# PIC18F26Q83 register map
Vendor: Microchip
Registers are 8-bit, read-write, reset 0x0 unless marked. A register's access mark holds for its fields unless they carry their own. Addresses are absolute, and some are shared; only a register's first bit layout is shown; [hi:lo] are bit positions; {n}, {i} and the like mark numbered series.

## CONFIG (part 1 of 3) — Configuration words, addresses in ProgramSpace
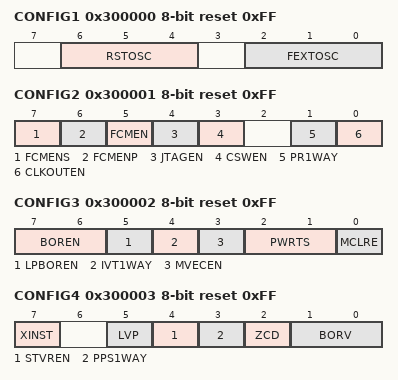
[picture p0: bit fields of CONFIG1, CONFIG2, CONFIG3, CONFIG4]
0x300000 CONFIG1 reset 0xFF — Configuration Byte 1
  [6:4] RSTOSC — Reset Oscillator Selection
    0=HFINTOSC_64MHZ (HFINTOSC with HFFRQ = 64 MHz and CDIV = 1:1); 2=EXTOSC_4PLL (EXTOSC with 4x PLL, with EXTOSC operating per FEXTOSC bits); 4=SOSC (Secondary Oscillator); 5=LFINTOSC (Low-Frequency Oscillator); 6=HFINTOSC_1MHZ (HFINTOSC with HFFRQ = 4 MHz and CDIV = 4:1); 7=EXTOSC (EXTOSC operating per FEXTOSC bits (device manufacturing default))
  [2:0] FEXTOSC — External Oscillator Selection
    0=LP (LP (crystal oscillator) optimized for 32.768 kHz); 1=XT (XT (crystal oscillator) above 100 kHz, below 8 MHz); 2=HS (HS (crystal oscillator) above 8 MHz); 4=OFF (Oscillator not enabled); 5=ECL (EC (external clock) below 100 kHz); 6=ECM (EC (external clock) for 500 kHz to 8 MHz); 7=ECH (EC (external clock) above 8 MHz)
0x300001 CONFIG2 reset 0xFF — Configuration byte 2
  [7] FCMENS — Fail-Safe Clock Monitor -Secondary XTAL Enable bit
    0=OFF (FSCM timer will not set FSCMS bit or OSFIF interrupt on Secondary XTAL failure); 1=ON (FSCM timer will set FSCMS bit and OSFIF interrupt on Secondary XTAL failure)
  [6] FCMENP — Fail-Safe Clock Monitor -Primary XTAL Enable bit
    0=OFF (FSCM timer will not set FSCMP bit or OSFIF interrupt on Primary XTAL failure); 1=ON (FSCM timer will set FSCMP bit and OSFIF interrupt on Primary XTAL failure)
  [5] FCMEN — Fail-Safe Clock Monitor Enable bit
    0=OFF (Fail-Safe Clock Monitor disabled); 1=ON (Fail-Safe Clock Monitor enabled)
  [4] JTAGEN — JTAG Enable bit
    1=ON (Enable JTAG Boundary Scan mode and pins); 0=OFF (Disable JTAG Boundary Scan mode, JTAG pins revert to user functions)
  [3] CSWEN — Clock Switch Enable bit
    0=OFF (The NOSC and NDIV bits cannot be changed by user software); 1=ON (Writing to NOSC and NDIV is allowed)
  [1] PR1WAY — PRLOCKED One-Way Set Enable bit
    1=ON (PRLOCKED bit can be cleared and set only once); 0=OFF (PRLOCKED bit can be set and cleared repeatedly)
  [0] CLKOUTEN — Clock out Enable bit
    1=OFF (CLKOUT function is disabled); 0=ON (CLKOUT function is enabled)
0x300002 CONFIG3 reset 0xFF — Configuration byte 3
  [7:6] BOREN — Brown-out Reset Enable bits
    3=SBORDIS (Brown-out Reset enabled , SBOREN bit is ignored); 2=NOSLP (Brown-out Reset enabled while running, disabled in Sleep; SBOREN is ignored); 1=ON (Brown-out Reset enabled according to SBOREN); 0=OFF (Brown-out Reset disabled)
  [5] LPBOREN — Low Power BOR Enable bit
    1=OFF (Low-Power BOR disabled); 0=ON (Low-Power BOR enabled)
  [4] IVT1WAY — IVTLOCK bit One-way set enable bit
    1=ON (IVTLOCKED bit can be cleared and set only once); 0=OFF (IVTLOCKED bit can be cleared and set repeatedly)
  [3] MVECEN — Multi-vector enable bit
    1=ON (Multi-vector enabled, Vector table used for interrupts); 0=OFF (Interrupt contoller does not use vector table to prioritze interrupts)
  [2:1] PWRTS — Power-up timer selection bits
    3=PWRT_OFF (PWRT is disabled); 2=PWRT_64 (PWRT set at 64ms); 1=PWRT_16 (PWRT set at 16ms); 0=PWRT_1 (PWRT set at 1ms)
  [0] MCLRE — MCLR Enable bit
    1=EXTMCLR (If LVP = 0, MCLR pin is MCLR; If LVP = 1, RE3 pin function is MCLR); 0=INTMCLR (If LVP = 0, MCLR pin function is port defined function; If LVP =1, RE3 pin fuction is MCLR)
0x300003 CONFIG4 reset 0xFF — Configuration byte 4
  [7] XINST — Extended Instruction Set Enable bit
    1=OFF (Extended Instruction Set and Indexed Addressing Mode disabled); 0=ON (Extended Instruction Set and Indexed Addressing Mode enabled)
  [5] LVP — Low Voltage Programming Enable bit
    1=ON (Low voltage programming enabled. MCLR/VPP pin function is MCLR. MCLRE configuration bit is ignored); 0=OFF (HV on MCLR/VPP must be used for programming)
  [4] STVREN — Stack Full/Underflow Reset Enable bit
    1=ON (Stack full/underflow will cause Reset); 0=OFF (Stack full/underflow will not cause Reset)
  [3] PPS1WAY — PPSLOCK bit One-Way Set Enable bit
    1=ON (PPSLOCKED bit can be cleared and set only once; PPS registers remain locked after one clear/set cycle); 0=OFF (PPSLOCKED bit can be set and cleared repeatedly (subject to the unlock sequence))
  [2] ZCD — ZCD Disable bit
    1=OFF (ZCD module is disabled. ZCD can be enabled by setting the ZCDSEN bit of ZCDCON); 0=ON (ZCD module is always enabled; ZCDMD and ZCDSEN bits are ignored)
  [1:0] BORV — Brown-out Reset Voltage Selection bits
    3=VBOR_1P9 (Brown-out Reset Voltage (VBOR) set to 1.9V); 2=VBOR_2P45 (Brown-out Reset Voltage (VBOR) set to 2.45V); 1=VBOR_2P7 (Brown-out Reset Voltage (VBOR) set to 2.7V); 0=VBOR_2P85 (Brown-out Reset Voltage (VBOR) set to 2.8V)
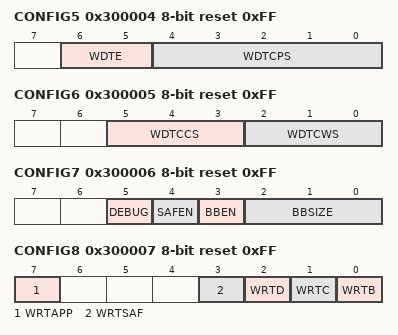
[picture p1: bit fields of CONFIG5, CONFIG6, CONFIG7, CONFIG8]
0x300004 CONFIG5 reset 0xFF — Configuration byte 5
  [6:5] WDTE — WDT operating mode
    0=OFF (WDT Disabled; SWDTEN is ignored); 1=SWDTEN (WDT enabled/disabled by SWDTEN bit); 2=NSLEEP (WDT enabled while sleep=0, suspended when sleep=1; SWDTEN ignored); 3=ON (WDT enabled regardless of sleep; SWDTEN is ignored)
  [4:0] WDTCPS — WDT Period selection bits
    0=Divider ratio 1:32; 1=Divider ratio 1:64; 2=Divider ratio 1:128; 3=Divider ratio 1:256; 4=Divider ratio 1:512; 5=Divider ratio 1:1024; 6=Divider ratio 1:2048; 7=Divider ratio 1:4096; 8=Divider ratio 1:8192; 9=Divider ratio 1:16384; 10=Divider ratio 1:32768; 11=Divider ratio 1:65536; 12=Divider ratio 1:131072; 13=Divider ratio 1:262144; 14=Divider ratio 1:524299; 15=Divider ratio 1:1048576; 16=Divider ratio 1:2097152; 17=Divider ratio 1:4194304; 18=Divider ratio 1:8388608; {v}=Divider ratio 1:32 (v=19..30); 31=Divider ratio 1:65536; software control of WDTPS
0x300005 CONFIG6 reset 0xFF — Configuration byte 6
  [5:3] WDTCCS — WDT input clock selector
    0=LFINTOSC (WDT reference clock is the 31.0 kHz LFINTOSC); 1=MFINTOSC (WDT reference clock is the 32kHz MFINTOSC output); 2=SOSC (WDT reference clock is SOSC); 7=SC (Software Control)
  [2:0] WDTCWS — WDT Window Select bits
    0=window delay = 87.5; no software control; keyed access required; 1=window delay = 75 percent of time; no software control; keyed access required; 2=window delay = 62.5 percent of time; no software control; keyed access required; 3=window delay = 50 percent of time; no software control; keyed access required; 4=window delay = 37.5 percent of time; no software control; keyed access required; 5=window delay = 25 percent of time; no software control; keyed access required; 6=window always open (100%); no software control; keyed access required; 7=window always open (100%); software control; keyed access not required
0x300006 CONFIG7 reset 0xFF — Configuration byte 7
  [5] DEBUG — Background Debugger
    1=OFF (Background Debugger disabled); 0=ON (background debugger enabled)
  [4] SAFEN — Storage Area Flash enable bit
    1=OFF (SAF disabled); 0=ON (SAF enabled)
  [3] BBEN — Boot Block enable bit
    1=OFF (Boot block disabled); 0=ON (Boot block enabled)
  [2:0] BBSIZE — Boot Block Size selection bits
    7=Boot Block size is 512 words; 6=Boot Block size is 1024 words; 5=Boot Block size is 2048 words; 4=Boot Block size is 4096 words; 3=Boot Block size is 8192 words; 2=Boot Block size is 16384 words; 1=Boot Block size is 32768 words
0x300007 CONFIG8 reset 0xFF — Configuration byte 8
  [7] WRTAPP — Application Block write protection bit
    1=OFF (Application Block not write protected); 0=ON (Application Block write protected)
  [3] WRTSAF — SAF Write protection bit
    1=OFF (SAF not Write Protected); 0=ON (SAF Write Protected)
  [2] WRTD — Data EEPROM Write Protection bit
    1=OFF (Data EEPROM not Write protected); 0=ON (Data EEPROM Write protected)
  [1] WRTC — Configuration Register Write Protection bit
    1=OFF (Configuration registers not Write protected); 0=ON (Configuration registers Write protected)
  [0] WRTB — Boot Block Write Protection bit
    1=OFF (Boot Block not Write protected); 0=ON (Boot Block Write protected)
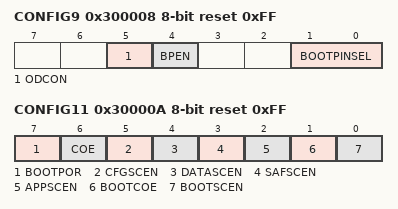
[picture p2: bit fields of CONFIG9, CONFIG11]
0x300008 CONFIG9 reset 0xFF
  [5] ODCON — CRC on boot output pin open drain bit
    1=OFF (Pin drives both high-going and low-going signals); 0=ON (Pin drives only low-going signals)
  [4] BPEN — CRC on boot output pin enable bit
    1=OFF (CRC on boot output pin disabled); 0=ON (CRC on boot output pin enabled, selected by BOOTPINSEL<1:0>)
  [1:0] BOOTPINSEL — CRC on boot output pin selection
    0=RA4 (CRC on boot output pin is RA4); 1=RA2 (CRC on boot output pin is RA2); 2=RC4 (CRC on boot output pin is RC4); 3=RC5 (CRC on boot output pin is RC5)
0x300009 CONFIG10 reset 0xFF — Configuration byte 10
  [0] CP — PFM and Data EEPROM Code Protection bit
    1=OFF (PFM and Data EEPROM code protection disabled); 0=ON (PFM and Data EEPROM code protection enabled)
0x30000A CONFIG11 reset 0xFF
  [7] BOOTPOR — Boot on CRC Enable bit
    1=OFF (CRC on boot will not run); 0=ON (CRC on boot will run)
  [6] COE — CRC on boot Continue on Error for non-boot areas bit
    1=HALT (CRC on boot will stop device if error is detected in non-boot areas); 0=CONTINUE (CRC on boot will allow device to continue code execution regardless of error detection in non-boot areas)
  [5] CFGSCEN — CRC on boot Config fuses scan enable
    1=OFF (CRC on boot will not include the configuration fuses in its calculation); 0=ON (CRC on boot will include the configuration fuses in its calculation)
  [4] DATASCEN — CRC on boot Data EEPROM scan enable
    1=OFF (CRC on boot will not include data EEPROM in its calculation); 0=ON (CRC on boot will include data EEPROM in its calculation)
  [3] SAFSCEN — CRC on boot SAF area scan enable
    1=OFF (CRC on boot will not include the SAF area of program memory in its calculation); 0=ON (CRC on boot will include the SAF area of program memory in its calculation)
  [2] APPSCEN — CRC on boot application code scan enable
    1=OFF (CRC on boot will not include the application area of program memory in its calculation); 0=ON (CRC on boot will include the application area of program memory in its calculation)
  [1] BOOTCOE — CRC on boot Continue on Error for boot areas bit
    1=HALT (CRC on boot will stop device if error is detected in boot areas); 0=CONTINUE (CRC on boot will allow device to continue code execution regardless of error detection in boot areas)
  [0] BOOTSCEN — CRC on boot scan enable for boot area
    1=OFF (CRC on boot will not include the boot area of program memory in its calculation); 0=ON (CRC on boot will include the boot area of program memory in its calculation)
0x30000B CONFIG12 reset 0xFF — Boot Sector Polynomial for CRC on boot bits 31-24
  [7:0] BCRCPOLT
    {v}=h{v:02} (Bits 31:24 of BCRCPOL are {0x0+v}) (v=0..9); 10=h0A (Bits 31:24 of BCRCPOL are 0x0A); 11=h0B (Bits 31:24 of BCRCPOL are 0x0B); 12=h0C (Bits 31:24 of BCRCPOL are 0x0C); 13=h0D (Bits 31:24 of BCRCPOL are 0x0D); 14=h0E (Bits 31:24 of BCRCPOL are 0x0E); 15=h0F (Bits 31:24 of BCRCPOL are 0x0F); {v}=h{v-6} (Bits 31:24 of BCRCPOL are {0x0+v}) (v=16..25); 26=h1A (Bits 31:24 of BCRCPOL are 0x1A); 27=h1B (Bits 31:24 of BCRCPOL are 0x1B); 28=h1C (Bits 31:24 of BCRCPOL are 0x1C); 29=h1D (Bits 31:24 of BCRCPOL are 0x1D); 30=h1E (Bits 31:24 of BCRCPOL are 0x1E); 31=h1F (Bits 31:24 of BCRCPOL are 0x1F); {v}=h{v-12} (Bits 31:24 of BCRCPOL are {0x0+v}) (v=32..41); 42=h2A (Bits 31:24 of BCRCPOL are 0x2A); 43=h2B (Bits 31:24 of BCRCPOL are 0x2B); 44=h2C (Bits 31:24 of BCRCPOL are 0x2C); 45=h2D (Bits 31:24 of BCRCPOL are 0x2D); 46=h2E (Bits 31:24 of BCRCPOL are 0x2E); 47=h2F (Bits 31:24 of BCRCPOL are 0x2F); {v}=h{v-18} (Bits 31:24 of BCRCPOL are {0x0+v}) (v=48..57); 58=h3A (Bits 31:24 of BCRCPOL are 0x3A); 59=h3B (Bits 31:24 of BCRCPOL are 0x3B); 60=h3C (Bits 31:24 of BCRCPOL are 0x3C); 61=h3D (Bits 31:24 of BCRCPOL are 0x3D); 62=h3E (Bits 31:24 of BCRCPOL are 0x3E); 63=h3F (Bits 31:24 of BCRCPOL are 0x3F); {v}=h{v-24} (Bits 31:24 of BCRCPOL are {0x0+v}) (v=64..73); 74=h4A (Bits 31:24 of BCRCPOL are 0x4A); 75=h4B (Bits 31:24 of BCRCPOL are 0x4B); 76=h4C (Bits 31:24 of BCRCPOL are 0x4C); 77=h4D (Bits 31:24 of BCRCPOL are 0x4D); 78=h4E (Bits 31:24 of BCRCPOL are 0x4E); 79=h4F (Bits 31:24 of BCRCPOL are 0x4F); {v}=h{v-30} (Bits 31:24 of BCRCPOL are {0x0+v}) (v=80..89); 90=h5A (Bits 31:24 of BCRCPOL are 0x5A); 91=h5B (Bits 31:24 of BCRCPOL are 0x5B); 92=h5C (Bits 31:24 of BCRCPOL are 0x5C); 93=h5D (Bits 31:24 of BCRCPOL are 0x5D); 94=h5E (Bits 31:24 of BCRCPOL are 0x5E); 95=h5F (Bits 31:24 of BCRCPOL are 0x5F); {v}=h{v-36} (Bits 31:24 of BCRCPOL are {0x0+v}) (v=96..105); 106=h6A (Bits 31:24 of BCRCPOL are 0x6A); 107=h6B (Bits 31:24 of BCRCPOL are 0x6B); 108=h6C (Bits 31:24 of BCRCPOL are 0x6C); 109=h6D (Bits 31:24 of BCRCPOL are 0x6D); 110=h6E (Bits 31:24 of BCRCPOL are 0x6E); 111=h6F (Bits 31:24 of BCRCPOL are 0x6F); {v}=h{v-42} (Bits 31:24 of BCRCPOL are {0x0+v}) (v=112..121); 122=h7A (Bits 31:24 of BCRCPOL are 0x7A); 123=h7B (Bits 31:24 of BCRCPOL are 0x7B); 124=h7C (Bits 31:24 of BCRCPOL are 0x7C); 125=h7D (Bits 31:24 of BCRCPOL are 0x7D); 126=h7E (Bits 31:24 of BCRCPOL are 0x7E); 127=h7F (Bits 31:24 of BCRCPOL are 0x7F); {v}=h{v-48} (Bits 31:24 of BCRCPOL are {0x0+v}) (v=128..137); 138=h8A (Bits 31:24 of BCRCPOL are 0x8A); 139=h8B (Bits 31:24 of BCRCPOL are 0x8B); 140=h8C (Bits 31:24 of BCRCPOL are 0x8C); 141=h8D (Bits 31:24 of BCRCPOL are 0x8D); 142=h8E (Bits 31:24 of BCRCPOL are 0x8E); 143=h8F (Bits 31:24 of BCRCPOL are 0x8F); {v}=h{v-54} (Bits 31:24 of BCRCPOL are {0x0+v}) (v=144..153); 154=h9A (Bits 31:24 of BCRCPOL are 0x9A); 155=h9B (Bits 31:24 of BCRCPOL are 0x9B); 156=h9C (Bits 31:24 of BCRCPOL are 0x9C); 157=h9D (Bits 31:24 of BCRCPOL are 0x9D); 158=h9E (Bits 31:24 of BCRCPOL are 0x9E); 159=h9F (Bits 31:24 of BCRCPOL are 0x9F); {v}=hA{v-160} (Bits 31:24 of BCRCPOL are {0x0+v}) (v=160..169); 170=hAA (Bits 31:24 of BCRCPOL are 0xAA); 171=hAB (Bits 31:24 of BCRCPOL are 0xAB); 172=hAC (Bits 31:24 of BCRCPOL are 0xAC); 173=hAD (Bits 31:24 of BCRCPOL are 0xAD); 174=hAE (Bits 31:24 of BCRCPOL are 0xAE); 175=hAF (Bits 31:24 of BCRCPOL are 0xAF); {v}=hB{v-176} (Bits 31:24 of BCRCPOL are {0x0+v}) (v=176..185); 186=hBA (Bits 31:24 of BCRCPOL are 0xBA); 187=hBB (Bits 31:24 of BCRCPOL are 0xBB); 188=hBC (Bits 31:24 of BCRCPOL are 0xBC); 189=hBD (Bits 31:24 of BCRCPOL are 0xBD); 190=hBE (Bits 31:24 of BCRCPOL are 0xBE); 191=hBF (Bits 31:24 of BCRCPOL are 0xBF); {v}=hC{v-192} (Bits 31:24 of BCRCPOL are {0x0+v}) (v=192..201); 202=hCA (Bits 31:24 of BCRCPOL are 0xCA); 203=hCB (Bits 31:24 of BCRCPOL are 0xCB); 204=hCC (Bits 31:24 of BCRCPOL are 0xCC); 205=hCD (Bits 31:24 of BCRCPOL are 0xCD); 206=hCE (Bits 31:24 of BCRCPOL are 0xCE); 207=hCF (Bits 31:24 of BCRCPOL are 0xCF); {v}=hD{v-208} (Bits 31:24 of BCRCPOL are {0x0+v}) (v=208..217); 218=hDA (Bits 31:24 of BCRCPOL are 0xDA); 219=hDB (Bits 31:24 of BCRCPOL are 0xDB); 220=hDC (Bits 31:24 of BCRCPOL are 0xDC); 221=hDD (Bits 31:24 of BCRCPOL are 0xDD); 222=hDE (Bits 31:24 of BCRCPOL are 0xDE); 223=hDF (Bits 31:24 of BCRCPOL are 0xDF); {v}=hE{v-224} (Bits 31:24 of BCRCPOL are {0x0+v}) (v=224..233); 234=hEA (Bits 31:24 of BCRCPOL are 0xEA); 235=hEB (Bits 31:24 of BCRCPOL are 0xEB); 236=hEC (Bits 31:24 of BCRCPOL are 0xEC); 237=hED (Bits 31:24 of BCRCPOL are 0xED); 238=hEE (Bits 31:24 of BCRCPOL are 0xEE); 239=hEF (Bits 31:24 of BCRCPOL are 0xEF); {v}=hF{v-240} (Bits 31:24 of BCRCPOL are {0x0+v}) (v=240..249); 250=hFA (Bits 31:24 of BCRCPOL are 0xFA); 251=hFB (Bits 31:24 of BCRCPOL are 0xFB); 252=hFC (Bits 31:24 of BCRCPOL are 0xFC); 253=hFD (Bits 31:24 of BCRCPOL are 0xFD); 254=hFE (Bits 31:24 of BCRCPOL are 0xFE); 255=hFF (Bits 31:24 of BCRCPOL are 0xFF)
0x30000C CONFIG13 reset 0xFF — Boot Sector Polynomial for CRC on boot bits 23-16
  [7:0] BCRCPOLU
    {v}=h{v:02} (Bits 23:16 of BCRCPOL are {0x0+v}) (v=0..9); 10=h0A (Bits 23:16 of BCRCPOL are 0x0A); 11=h0B (Bits 23:16 of BCRCPOL are 0x0B); 12=h0C (Bits 23:16 of BCRCPOL are 0x0C); 13=h0D (Bits 23:16 of BCRCPOL are 0x0D); 14=h0E (Bits 23:16 of BCRCPOL are 0x0E); 15=h0F (Bits 23:16 of BCRCPOL are 0x0F); {v}=h{v-6} (Bits 23:16 of BCRCPOL are {0x0+v}) (v=16..25); 26=h1A (Bits 23:16 of BCRCPOL are 0x1A); 27=h1B (Bits 23:16 of BCRCPOL are 0x1B); 28=h1C (Bits 23:16 of BCRCPOL are 0x1C); 29=h1D (Bits 23:16 of BCRCPOL are 0x1D); 30=h1E (Bits 23:16 of BCRCPOL are 0x1E); 31=h1F (Bits 23:16 of BCRCPOL are 0x1F); {v}=h{v-12} (Bits 23:16 of BCRCPOL are {0x0+v}) (v=32..41); 42=h2A (Bits 23:16 of BCRCPOL are 0x2A); 43=h2B (Bits 23:16 of BCRCPOL are 0x2B); 44=h2C (Bits 23:16 of BCRCPOL are 0x2C); 45=h2D (Bits 23:16 of BCRCPOL are 0x2D); 46=h2E (Bits 23:16 of BCRCPOL are 0x2E); 47=h2F (Bits 23:16 of BCRCPOL are 0x2F); {v}=h{v-18} (Bits 23:16 of BCRCPOL are {0x0+v}) (v=48..57); 58=h3A (Bits 23:16 of BCRCPOL are 0x3A); 59=h3B (Bits 23:16 of BCRCPOL are 0x3B); 60=h3C (Bits 23:16 of BCRCPOL are 0x3C); 61=h3D (Bits 23:16 of BCRCPOL are 0x3D); 62=h3E (Bits 23:16 of BCRCPOL are 0x3E); 63=h3F (Bits 23:16 of BCRCPOL are 0x3F); {v}=h{v-24} (Bits 23:16 of BCRCPOL are {0x0+v}) (v=64..73); 74=h4A (Bits 23:16 of BCRCPOL are 0x4A); 75=h4B (Bits 23:16 of BCRCPOL are 0x4B); 76=h4C (Bits 23:16 of BCRCPOL are 0x4C); 77=h4D (Bits 23:16 of BCRCPOL are 0x4D); 78=h4E (Bits 23:16 of BCRCPOL are 0x4E); 79=h4F (Bits 23:16 of BCRCPOL are 0x4F); {v}=h{v-30} (Bits 23:16 of BCRCPOL are {0x0+v}) (v=80..89); 90=h5A (Bits 23:16 of BCRCPOL are 0x5A); 91=h5B (Bits 23:16 of BCRCPOL are 0x5B); 92=h5C (Bits 23:16 of BCRCPOL are 0x5C); 93=h5D (Bits 23:16 of BCRCPOL are 0x5D); 94=h5E (Bits 23:16 of BCRCPOL are 0x5E); 95=h5F (Bits 23:16 of BCRCPOL are 0x5F); {v}=h{v-36} (Bits 23:16 of BCRCPOL are {0x0+v}) (v=96..105); 106=h6A (Bits 23:16 of BCRCPOL are 0x6A); 107=h6B (Bits 23:16 of BCRCPOL are 0x6B); 108=h6C (Bits 23:16 of BCRCPOL are 0x6C); 109=h6D (Bits 23:16 of BCRCPOL are 0x6D); 110=h6E (Bits 23:16 of BCRCPOL are 0x6E); 111=h6F (Bits 23:16 of BCRCPOL are 0x6F); {v}=h{v-42} (Bits 23:16 of BCRCPOL are {0x0+v}) (v=112..121); 122=h7A (Bits 23:16 of BCRCPOL are 0x7A); 123=h7B (Bits 23:16 of BCRCPOL are 0x7B); 124=h7C (Bits 23:16 of BCRCPOL are 0x7C); 125=h7D (Bits 23:16 of BCRCPOL are 0x7D); 126=h7E (Bits 23:16 of BCRCPOL are 0x7E); 127=h7F (Bits 23:16 of BCRCPOL are 0x7F); {v}=h{v-48} (Bits 23:16 of BCRCPOL are {0x0+v}) (v=128..137); 138=h8A (Bits 23:16 of BCRCPOL are 0x8A); 139=h8B (Bits 23:16 of BCRCPOL are 0x8B); 140=h8C (Bits 23:16 of BCRCPOL are 0x8C); 141=h8D (Bits 23:16 of BCRCPOL are 0x8D); 142=h8E (Bits 23:16 of BCRCPOL are 0x8E); 143=h8F (Bits 23:16 of BCRCPOL are 0x8F); {v}=h{v-54} (Bits 23:16 of BCRCPOL are {0x0+v}) (v=144..153); 154=h9A (Bits 23:16 of BCRCPOL are 0x9A); 155=h9B (Bits 23:16 of BCRCPOL are 0x9B); 156=h9C (Bits 23:16 of BCRCPOL are 0x9C); 157=h9D (Bits 23:16 of BCRCPOL are 0x9D); 158=h9E (Bits 23:16 of BCRCPOL are 0x9E); 159=h9F (Bits 23:16 of BCRCPOL are 0x9F); {v}=hA{v-160} (Bits 23:16 of BCRCPOL are {0x0+v}) (v=160..169); 170=hAA (Bits 23:16 of BCRCPOL are 0xAA); 171=hAB (Bits 23:16 of BCRCPOL are 0xAB); 172=hAC (Bits 23:16 of BCRCPOL are 0xAC); 173=hAD (Bits 23:16 of BCRCPOL are 0xAD); 174=hAE (Bits 23:16 of BCRCPOL are 0xAE); 175=hAF (Bits 23:16 of BCRCPOL are 0xAF); {v}=hB{v-176} (Bits 23:16 of BCRCPOL are {0x0+v}) (v=176..185); 186=hBA (Bits 23:16 of BCRCPOL are 0xBA); 187=hBB (Bits 23:16 of BCRCPOL are 0xBB); 188=hBC (Bits 23:16 of BCRCPOL are 0xBC); 189=hBD (Bits 23:16 of BCRCPOL are 0xBD); 190=hBE (Bits 23:16 of BCRCPOL are 0xBE); 191=hBF (Bits 23:16 of BCRCPOL are 0xBF); {v}=hC{v-192} (Bits 23:16 of BCRCPOL are {0x0+v}) (v=192..201); 202=hCA (Bits 23:16 of BCRCPOL are 0xCA); 203=hCB (Bits 23:16 of BCRCPOL are 0xCB); 204=hCC (Bits 23:16 of BCRCPOL are 0xCC); 205=hCD (Bits 23:16 of BCRCPOL are 0xCD); 206=hCE (Bits 23:16 of BCRCPOL are 0xCE); 207=hCF (Bits 23:16 of BCRCPOL are 0xCF); {v}=hD{v-208} (Bits 23:16 of BCRCPOL are {0x0+v}) (v=208..217); 218=hDA (Bits 23:16 of BCRCPOL are 0xDA); 219=hDB (Bits 23:16 of BCRCPOL are 0xDB); 220=hDC (Bits 23:16 of BCRCPOL are 0xDC); 221=hDD (Bits 23:16 of BCRCPOL are 0xDD); 222=hDE (Bits 23:16 of BCRCPOL are 0xDE); 223=hDF (Bits 23:16 of BCRCPOL are 0xDF); {v}=hE{v-224} (Bits 23:16 of BCRCPOL are {0x0+v}) (v=224..233); 234=hEA (Bits 23:16 of BCRCPOL are 0xEA); 235=hEB (Bits 23:16 of BCRCPOL are 0xEB); 236=hEC (Bits 23:16 of BCRCPOL are 0xEC); 237=hED (Bits 23:16 of BCRCPOL are 0xED); 238=hEE (Bits 23:16 of BCRCPOL are 0xEE); 239=hEF (Bits 23:16 of BCRCPOL are 0xEF); {v}=hF{v-240} (Bits 23:16 of BCRCPOL are {0x0+v}) (v=240..249); 250=hFA (Bits 23:16 of BCRCPOL are 0xFA); 251=hFB (Bits 23:16 of BCRCPOL are 0xFB); 252=hFC (Bits 23:16 of BCRCPOL are 0xFC); 253=hFD (Bits 23:16 of BCRCPOL are 0xFD); 254=hFE (Bits 23:16 of BCRCPOL are 0xFE); 255=hFF (Bits 23:16 of BCRCPOL are 0xFF)
0x30000D CONFIG14 reset 0xFF — Boot Sector Polynomial for CRC on boot bits 15-8
  [7:0] BCRCPOLH
    {v}=h{v:02} (Bits 15:8 of BCRCPOL are {0x0+v}) (v=0..9); 10=h0A (Bits 15:8 of BCRCPOL are 0x0A); 11=h0B (Bits 15:8 of BCRCPOL are 0x0B); 12=h0C (Bits 15:8 of BCRCPOL are 0x0C); 13=h0D (Bits 15:8 of BCRCPOL are 0x0D); 14=h0E (Bits 15:8 of BCRCPOL are 0x0E); 15=h0F (Bits 15:8 of BCRCPOL are 0x0F); {v}=h{v-6} (Bits 15:8 of BCRCPOL are {0x0+v}) (v=16..25); 26=h1A (Bits 15:8 of BCRCPOL are 0x1A); 27=h1B (Bits 15:8 of BCRCPOL are 0x1B); 28=h1C (Bits 15:8 of BCRCPOL are 0x1C); 29=h1D (Bits 15:8 of BCRCPOL are 0x1D); 30=h1E (Bits 15:8 of BCRCPOL are 0x1E); 31=h1F (Bits 15:8 of BCRCPOL are 0x1F); {v}=h{v-12} (Bits 15:8 of BCRCPOL are {0x0+v}) (v=32..41); 42=h2A (Bits 15:8 of BCRCPOL are 0x2A); 43=h2B (Bits 15:8 of BCRCPOL are 0x2B); 44=h2C (Bits 15:8 of BCRCPOL are 0x2C); 45=h2D (Bits 15:8 of BCRCPOL are 0x2D); 46=h2E (Bits 15:8 of BCRCPOL are 0x2E); 47=h2F (Bits 15:8 of BCRCPOL are 0x2F); {v}=h{v-18} (Bits 15:8 of BCRCPOL are {0x0+v}) (v=48..57); 58=h3A (Bits 15:8 of BCRCPOL are 0x3A); 59=h3B (Bits 15:8 of BCRCPOL are 0x3B); 60=h3C (Bits 15:8 of BCRCPOL are 0x3C); 61=h3D (Bits 15:8 of BCRCPOL are 0x3D); 62=h3E (Bits 15:8 of BCRCPOL are 0x3E); 63=h3F (Bits 15:8 of BCRCPOL are 0x3F); {v}=h{v-24} (Bits 15:8 of BCRCPOL are {0x0+v}) (v=64..73); 74=h4A (Bits 15:8 of BCRCPOL are 0x4A); 75=h4B (Bits 15:8 of BCRCPOL are 0x4B); 76=h4C (Bits 15:8 of BCRCPOL are 0x4C); 77=h4D (Bits 15:8 of BCRCPOL are 0x4D); 78=h4E (Bits 15:8 of BCRCPOL are 0x4E); 79=h4F (Bits 15:8 of BCRCPOL are 0x4F); {v}=h{v-30} (Bits 15:8 of BCRCPOL are {0x0+v}) (v=80..89); 90=h5A (Bits 15:8 of BCRCPOL are 0x5A); 91=h5B (Bits 15:8 of BCRCPOL are 0x5B); 92=h5C (Bits 15:8 of BCRCPOL are 0x5C); 93=h5D (Bits 15:8 of BCRCPOL are 0x5D); 94=h5E (Bits 15:8 of BCRCPOL are 0x5E); 95=h5F (Bits 15:8 of BCRCPOL are 0x5F); {v}=h{v-36} (Bits 15:8 of BCRCPOL are {0x0+v}) (v=96..105); 106=h6A (Bits 15:8 of BCRCPOL are 0x6A); 107=h6B (Bits 15:8 of BCRCPOL are 0x6B); 108=h6C (Bits 15:8 of BCRCPOL are 0x6C); 109=h6D (Bits 15:8 of BCRCPOL are 0x6D); 110=h6E (Bits 15:8 of BCRCPOL are 0x6E); 111=h6F (Bits 15:8 of BCRCPOL are 0x6F); {v}=h{v-42} (Bits 15:8 of BCRCPOL are {0x0+v}) (v=112..121); 122=h7A (Bits 15:8 of BCRCPOL are 0x7A); 123=h7B (Bits 15:8 of BCRCPOL are 0x7B); 124=h7C (Bits 15:8 of BCRCPOL are 0x7C); 125=h7D (Bits 15:8 of BCRCPOL are 0x7D); 126=h7E (Bits 15:8 of BCRCPOL are 0x7E); 127=h7F (Bits 15:8 of BCRCPOL are 0x7F); {v}=h{v-48} (Bits 15:8 of BCRCPOL are {0x0+v}) (v=128..137); 138=h8A (Bits 15:8 of BCRCPOL are 0x8A); 139=h8B (Bits 15:8 of BCRCPOL are 0x8B); 140=h8C (Bits 15:8 of BCRCPOL are 0x8C); 141=h8D (Bits 15:8 of BCRCPOL are 0x8D); 142=h8E (Bits 15:8 of BCRCPOL are 0x8E); 143=h8F (Bits 15:8 of BCRCPOL are 0x8F); {v}=h{v-54} (Bits 15:8 of BCRCPOL are {0x0+v}) (v=144..153); 154=h9A (Bits 15:8 of BCRCPOL are 0x9A); 155=h9B (Bits 15:8 of BCRCPOL are 0x9B); 156=h9C (Bits 15:8 of BCRCPOL are 0x9C); 157=h9D (Bits 15:8 of BCRCPOL are 0x9D); 158=h9E (Bits 15:8 of BCRCPOL are 0x9E); 159=h9F (Bits 15:8 of BCRCPOL are 0x9F); {v}=hA{v-160} (Bits 15:8 of BCRCPOL are {0x0+v}) (v=160..169); 170=hAA (Bits 15:8 of BCRCPOL are 0xAA); 171=hAB (Bits 15:8 of BCRCPOL are 0xAB); 172=hAC (Bits 15:8 of BCRCPOL are 0xAC); 173=hAD (Bits 15:8 of BCRCPOL are 0xAD); 174=hAE (Bits 15:8 of BCRCPOL are 0xAE); 175=hAF (Bits 15:8 of BCRCPOL are 0xAF); {v}=hB{v-176} (Bits 15:8 of BCRCPOL are {0x0+v}) (v=176..185); 186=hBA (Bits 15:8 of BCRCPOL are 0xBA); 187=hBB (Bits 15:8 of BCRCPOL are 0xBB); 188=hBC (Bits 15:8 of BCRCPOL are 0xBC); 189=hBD (Bits 15:8 of BCRCPOL are 0xBD); 190=hBE (Bits 15:8 of BCRCPOL are 0xBE); 191=hBF (Bits 15:8 of BCRCPOL are 0xBF); {v}=hC{v-192} (Bits 15:8 of BCRCPOL are {0x0+v}) (v=192..201); 202=hCA (Bits 15:8 of BCRCPOL are 0xCA); 203=hCB (Bits 15:8 of BCRCPOL are 0xCB); 204=hCC (Bits 15:8 of BCRCPOL are 0xCC); 205=hCD (Bits 15:8 of BCRCPOL are 0xCD); 206=hCE (Bits 15:8 of BCRCPOL are 0xCE); 207=hCF (Bits 15:8 of BCRCPOL are 0xCF); {v}=hD{v-208} (Bits 15:8 of BCRCPOL are {0x0+v}) (v=208..217); 218=hDA (Bits 15:8 of BCRCPOL are 0xDA); 219=hDB (Bits 15:8 of BCRCPOL are 0xDB); 220=hDC (Bits 15:8 of BCRCPOL are 0xDC); 221=hDD (Bits 15:8 of BCRCPOL are 0xDD); 222=hDE (Bits 15:8 of BCRCPOL are 0xDE); 223=hDF (Bits 15:8 of BCRCPOL are 0xDF); {v}=hE{v-224} (Bits 15:8 of BCRCPOL are {0x0+v}) (v=224..233); 234=hEA (Bits 15:8 of BCRCPOL are 0xEA); 235=hEB (Bits 15:8 of BCRCPOL are 0xEB); 236=hEC (Bits 15:8 of BCRCPOL are 0xEC); 237=hED (Bits 15:8 of BCRCPOL are 0xED); 238=hEE (Bits 15:8 of BCRCPOL are 0xEE); 239=hEF (Bits 15:8 of BCRCPOL are 0xEF); {v}=hF{v-240} (Bits 15:8 of BCRCPOL are {0x0+v}) (v=240..249); 250=hFA (Bits 15:8 of BCRCPOL are 0xFA); 251=hFB (Bits 15:8 of BCRCPOL are 0xFB); 252=hFC (Bits 15:8 of BCRCPOL are 0xFC); 253=hFD (Bits 15:8 of BCRCPOL are 0xFD); 254=hFE (Bits 15:8 of BCRCPOL are 0xFE); 255=hFF (Bits 15:8 of BCRCPOL are 0xFF)
0x30000E CONFIG15 reset 0xFF — Boot Sector Polynomial for CRC on boot bits 7-0
  [7:0] BCRCPOLL
    {v}=h{v:02} (Bits 7:0 of BCRCPOL are {0x0+v}) (v=0..9); 10=h0A (Bits 7:0 of BCRCPOL are 0x0A); 11=h0B (Bits 7:0 of BCRCPOL are 0x0B); 12=h0C (Bits 7:0 of BCRCPOL are 0x0C); 13=h0D (Bits 7:0 of BCRCPOL are 0x0D); 14=h0E (Bits 7:0 of BCRCPOL are 0x0E); 15=h0F (Bits 7:0 of BCRCPOL are 0x0F); {v}=h{v-6} (Bits 7:0 of BCRCPOL are {0x0+v}) (v=16..25); 26=h1A (Bits 7:0 of BCRCPOL are 0x1A); 27=h1B (Bits 7:0 of BCRCPOL are 0x1B); 28=h1C (Bits 7:0 of BCRCPOL are 0x1C); 29=h1D (Bits 7:0 of BCRCPOL are 0x1D); 30=h1E (Bits 7:0 of BCRCPOL are 0x1E); 31=h1F (Bits 7:0 of BCRCPOL are 0x1F); {v}=h{v-12} (Bits 7:0 of BCRCPOL are {0x0+v}) (v=32..41); 42=h2A (Bits 7:0 of BCRCPOL are 0x2A); 43=h2B (Bits 7:0 of BCRCPOL are 0x2B); 44=h2C (Bits 7:0 of BCRCPOL are 0x2C); 45=h2D (Bits 7:0 of BCRCPOL are 0x2D); 46=h2E (Bits 7:0 of BCRCPOL are 0x2E); 47=h2F (Bits 7:0 of BCRCPOL are 0x2F); {v}=h{v-18} (Bits 7:0 of BCRCPOL are {0x0+v}) (v=48..57); 58=h3A (Bits 7:0 of BCRCPOL are 0x3A); 59=h3B (Bits 7:0 of BCRCPOL are 0x3B); 60=h3C (Bits 7:0 of BCRCPOL are 0x3C); 61=h3D (Bits 7:0 of BCRCPOL are 0x3D); 62=h3E (Bits 7:0 of BCRCPOL are 0x3E); 63=h3F (Bits 7:0 of BCRCPOL are 0x3F); {v}=h{v-24} (Bits 7:0 of BCRCPOL are {0x0+v}) (v=64..73); 74=h4A (Bits 7:0 of BCRCPOL are 0x4A); 75=h4B (Bits 7:0 of BCRCPOL are 0x4B); 76=h4C (Bits 7:0 of BCRCPOL are 0x4C); 77=h4D (Bits 7:0 of BCRCPOL are 0x4D); 78=h4E (Bits 7:0 of BCRCPOL are 0x4E); 79=h4F (Bits 7:0 of BCRCPOL are 0x4F); {v}=h{v-30} (Bits 7:0 of BCRCPOL are {0x0+v}) (v=80..89); 90=h5A (Bits 7:0 of BCRCPOL are 0x5A); 91=h5B (Bits 7:0 of BCRCPOL are 0x5B); 92=h5C (Bits 7:0 of BCRCPOL are 0x5C); 93=h5D (Bits 7:0 of BCRCPOL are 0x5D); 94=h5E (Bits 7:0 of BCRCPOL are 0x5E); 95=h5F (Bits 7:0 of BCRCPOL are 0x5F); {v}=h{v-36} (Bits 7:0 of BCRCPOL are {0x0+v}) (v=96..105); 106=h6A (Bits 7:0 of BCRCPOL are 0x6A); 107=h6B (Bits 7:0 of BCRCPOL are 0x6B); 108=h6C (Bits 7:0 of BCRCPOL are 0x6C); 109=h6D (Bits 7:0 of BCRCPOL are 0x6D); 110=h6E (Bits 7:0 of BCRCPOL are 0x6E); 111=h6F (Bits 7:0 of BCRCPOL are 0x6F); {v}=h{v-42} (Bits 7:0 of BCRCPOL are {0x0+v}) (v=112..121); 122=h7A (Bits 7:0 of BCRCPOL are 0x7A); 123=h7B (Bits 7:0 of BCRCPOL are 0x7B); 124=h7C (Bits 7:0 of BCRCPOL are 0x7C); 125=h7D (Bits 7:0 of BCRCPOL are 0x7D); 126=h7E (Bits 7:0 of BCRCPOL are 0x7E); 127=h7F (Bits 7:0 of BCRCPOL are 0x7F); {v}=h{v-48} (Bits 7:0 of BCRCPOL are {0x0+v}) (v=128..137); 138=h8A (Bits 7:0 of BCRCPOL are 0x8A); 139=h8B (Bits 7:0 of BCRCPOL are 0x8B); 140=h8C (Bits 7:0 of BCRCPOL are 0x8C); 141=h8D (Bits 7:0 of BCRCPOL are 0x8D); 142=h8E (Bits 7:0 of BCRCPOL are 0x8E); 143=h8F (Bits 7:0 of BCRCPOL are 0x8F); {v}=h{v-54} (Bits 7:0 of BCRCPOL are {0x0+v}) (v=144..153); 154=h9A (Bits 7:0 of BCRCPOL are 0x9A); 155=h9B (Bits 7:0 of BCRCPOL are 0x9B); 156=h9C (Bits 7:0 of BCRCPOL are 0x9C); 157=h9D (Bits 7:0 of BCRCPOL are 0x9D); 158=h9E (Bits 7:0 of BCRCPOL are 0x9E); 159=h9F (Bits 7:0 of BCRCPOL are 0x9F); {v}=hA{v-160} (Bits 7:0 of BCRCPOL are {0x0+v}) (v=160..169); 170=hAA (Bits 7:0 of BCRCPOL are 0xAA); 171=hAB (Bits 7:0 of BCRCPOL are 0xAB); 172=hAC (Bits 7:0 of BCRCPOL are 0xAC); 173=hAD (Bits 7:0 of BCRCPOL are 0xAD); 174=hAE (Bits 7:0 of BCRCPOL are 0xAE); 175=hAF (Bits 7:0 of BCRCPOL are 0xAF); {v}=hB{v-176} (Bits 7:0 of BCRCPOL are {0x0+v}) (v=176..185); 186=hBA (Bits 7:0 of BCRCPOL are 0xBA); 187=hBB (Bits 7:0 of BCRCPOL are 0xBB); 188=hBC (Bits 7:0 of BCRCPOL are 0xBC); 189=hBD (Bits 7:0 of BCRCPOL are 0xBD); 190=hBE (Bits 7:0 of BCRCPOL are 0xBE); 191=hBF (Bits 7:0 of BCRCPOL are 0xBF); {v}=hC{v-192} (Bits 7:0 of BCRCPOL are {0x0+v}) (v=192..201); 202=hCA (Bits 7:0 of BCRCPOL are 0xCA); 203=hCB (Bits 7:0 of BCRCPOL are 0xCB); 204=hCC (Bits 7:0 of BCRCPOL are 0xCC); 205=hCD (Bits 7:0 of BCRCPOL are 0xCD); 206=hCE (Bits 7:0 of BCRCPOL are 0xCE); 207=hCF (Bits 7:0 of BCRCPOL are 0xCF); {v}=hD{v-208} (Bits 7:0 of BCRCPOL are {0x0+v}) (v=208..217); 218=hDA (Bits 7:0 of BCRCPOL are 0xDA); 219=hDB (Bits 7:0 of BCRCPOL are 0xDB); 220=hDC (Bits 7:0 of BCRCPOL are 0xDC); 221=hDD (Bits 7:0 of BCRCPOL are 0xDD); 222=hDE (Bits 7:0 of BCRCPOL are 0xDE); 223=hDF (Bits 7:0 of BCRCPOL are 0xDF); {v}=hE{v-224} (Bits 7:0 of BCRCPOL are {0x0+v}) (v=224..233); 234=hEA (Bits 7:0 of BCRCPOL are 0xEA); 235=hEB (Bits 7:0 of BCRCPOL are 0xEB); 236=hEC (Bits 7:0 of BCRCPOL are 0xEC); 237=hED (Bits 7:0 of BCRCPOL are 0xED); 238=hEE (Bits 7:0 of BCRCPOL are 0xEE); 239=hEF (Bits 7:0 of BCRCPOL are 0xEF); {v}=hF{v-240} (Bits 7:0 of BCRCPOL are {0x0+v}) (v=240..249); 250=hFA (Bits 7:0 of BCRCPOL are 0xFA); 251=hFB (Bits 7:0 of BCRCPOL are 0xFB); 252=hFC (Bits 7:0 of BCRCPOL are 0xFC); 253=hFD (Bits 7:0 of BCRCPOL are 0xFD); 254=hFE (Bits 7:0 of BCRCPOL are 0xFE); 255=hFF (Bits 7:0 of BCRCPOL are 0xFF)
0x30000F CONFIG16 reset 0xFF — Boot Sector Seed for CRC on boot bits 31-24
  [7:0] BCRCSEEDT
    {v}=h{v:02} (Bits 31:24 of BCRCSEED are {0x0+v}) (v=0..9); 10=h0A (Bits 31:24 of BCRCSEED are 0x0A); 11=h0B (Bits 31:24 of BCRCSEED are 0x0B); 12=h0C (Bits 31:24 of BCRCSEED are 0x0C); 13=h0D (Bits 31:24 of BCRCSEED are 0x0D); 14=h0E (Bits 31:24 of BCRCSEED are 0x0E); 15=h0F (Bits 31:24 of BCRCSEED are 0x0F); {v}=h{v-6} (Bits 31:24 of BCRCSEED are {0x0+v}) (v=16..25); 26=h1A (Bits 31:24 of BCRCSEED are 0x1A); 27=h1B (Bits 31:24 of BCRCSEED are 0x1B); 28=h1C (Bits 31:24 of BCRCSEED are 0x1C); 29=h1D (Bits 31:24 of BCRCSEED are 0x1D); 30=h1E (Bits 31:24 of BCRCSEED are 0x1E); 31=h1F (Bits 31:24 of BCRCSEED are 0x1F); {v}=h{v-12} (Bits 31:24 of BCRCSEED are {0x0+v}) (v=32..41); 42=h2A (Bits 31:24 of BCRCSEED are 0x2A); 43=h2B (Bits 31:24 of BCRCSEED are 0x2B); 44=h2C (Bits 31:24 of BCRCSEED are 0x2C); 45=h2D (Bits 31:24 of BCRCSEED are 0x2D); 46=h2E (Bits 31:24 of BCRCSEED are 0x2E); 47=h2F (Bits 31:24 of BCRCSEED are 0x2F); {v}=h{v-18} (Bits 31:24 of BCRCSEED are {0x0+v}) (v=48..57); 58=h3A (Bits 31:24 of BCRCSEED are 0x3A); 59=h3B (Bits 31:24 of BCRCSEED are 0x3B); 60=h3C (Bits 31:24 of BCRCSEED are 0x3C); 61=h3D (Bits 31:24 of BCRCSEED are 0x3D); 62=h3E (Bits 31:24 of BCRCSEED are 0x3E); 63=h3F (Bits 31:24 of BCRCSEED are 0x3F); {v}=h{v-24} (Bits 31:24 of BCRCSEED are {0x0+v}) (v=64..73); 74=h4A (Bits 31:24 of BCRCSEED are 0x4A); 75=h4B (Bits 31:24 of BCRCSEED are 0x4B); 76=h4C (Bits 31:24 of BCRCSEED are 0x4C); 77=h4D (Bits 31:24 of BCRCSEED are 0x4D); 78=h4E (Bits 31:24 of BCRCSEED are 0x4E); 79=h4F (Bits 31:24 of BCRCSEED are 0x4F); {v}=h{v-30} (Bits 31:24 of BCRCSEED are {0x0+v}) (v=80..89); 90=h5A (Bits 31:24 of BCRCSEED are 0x5A); 91=h5B (Bits 31:24 of BCRCSEED are 0x5B); 92=h5C (Bits 31:24 of BCRCSEED are 0x5C); 93=h5D (Bits 31:24 of BCRCSEED are 0x5D); 94=h5E (Bits 31:24 of BCRCSEED are 0x5E); 95=h5F (Bits 31:24 of BCRCSEED are 0x5F); {v}=h{v-36} (Bits 31:24 of BCRCSEED are {0x0+v}) (v=96..105); 106=h6A (Bits 31:24 of BCRCSEED are 0x6A); 107=h6B (Bits 31:24 of BCRCSEED are 0x6B); 108=h6C (Bits 31:24 of BCRCSEED are 0x6C); 109=h6D (Bits 31:24 of BCRCSEED are 0x6D); 110=h6E (Bits 31:24 of BCRCSEED are 0x6E); 111=h6F (Bits 31:24 of BCRCSEED are 0x6F); {v}=h{v-42} (Bits 31:24 of BCRCSEED are {0x0+v}) (v=112..121); 122=h7A (Bits 31:24 of BCRCSEED are 0x7A); 123=h7B (Bits 31:24 of BCRCSEED are 0x7B); 124=h7C (Bits 31:24 of BCRCSEED are 0x7C); 125=h7D (Bits 31:24 of BCRCSEED are 0x7D); 126=h7E (Bits 31:24 of BCRCSEED are 0x7E); 127=h7F (Bits 31:24 of BCRCSEED are 0x7F); {v}=h{v-48} (Bits 31:24 of BCRCSEED are {0x0+v}) (v=128..137); 138=h8A (Bits 31:24 of BCRCSEED are 0x8A); 139=h8B (Bits 31:24 of BCRCSEED are 0x8B); 140=h8C (Bits 31:24 of BCRCSEED are 0x8C); 141=h8D (Bits 31:24 of BCRCSEED are 0x8D); 142=h8E (Bits 31:24 of BCRCSEED are 0x8E); 143=h8F (Bits 31:24 of BCRCSEED are 0x8F); {v}=h{v-54} (Bits 31:24 of BCRCSEED are {0x0+v}) (v=144..153); 154=h9A (Bits 31:24 of BCRCSEED are 0x9A); 155=h9B (Bits 31:24 of BCRCSEED are 0x9B); 156=h9C (Bits 31:24 of BCRCSEED are 0x9C); 157=h9D (Bits 31:24 of BCRCSEED are 0x9D); 158=h9E (Bits 31:24 of BCRCSEED are 0x9E); 159=h9F (Bits 31:24 of BCRCSEED are 0x9F); {v}=hA{v-160} (Bits 31:24 of BCRCSEED are {0x0+v}) (v=160..169); 170=hAA (Bits 31:24 of BCRCSEED are 0xAA); 171=hAB (Bits 31:24 of BCRCSEED are 0xAB); 172=hAC (Bits 31:24 of BCRCSEED are 0xAC); 173=hAD (Bits 31:24 of BCRCSEED are 0xAD); 174=hAE (Bits 31:24 of BCRCSEED are 0xAE); 175=hAF (Bits 31:24 of BCRCSEED are 0xAF); {v}=hB{v-176} (Bits 31:24 of BCRCSEED are {0x0+v}) (v=176..185); 186=hBA (Bits 31:24 of BCRCSEED are 0xBA); 187=hBB (Bits 31:24 of BCRCSEED are 0xBB); 188=hBC (Bits 31:24 of BCRCSEED are 0xBC); 189=hBD (Bits 31:24 of BCRCSEED are 0xBD); 190=hBE (Bits 31:24 of BCRCSEED are 0xBE); 191=hBF (Bits 31:24 of BCRCSEED are 0xBF); {v}=hC{v-192} (Bits 31:24 of BCRCSEED are {0x0+v}) (v=192..201); 202=hCA (Bits 31:24 of BCRCSEED are 0xCA); 203=hCB (Bits 31:24 of BCRCSEED are 0xCB); 204=hCC (Bits 31:24 of BCRCSEED are 0xCC); 205=hCD (Bits 31:24 of BCRCSEED are 0xCD); 206=hCE (Bits 31:24 of BCRCSEED are 0xCE); 207=hCF (Bits 31:24 of BCRCSEED are 0xCF); {v}=hD{v-208} (Bits 31:24 of BCRCSEED are {0x0+v}) (v=208..217); 218=hDA (Bits 31:24 of BCRCSEED are 0xDA); 219=hDB (Bits 31:24 of BCRCSEED are 0xDB); 220=hDC (Bits 31:24 of BCRCSEED are 0xDC); 221=hDD (Bits 31:24 of BCRCSEED are 0xDD); 222=hDE (Bits 31:24 of BCRCSEED are 0xDE); 223=hDF (Bits 31:24 of BCRCSEED are 0xDF); {v}=hE{v-224} (Bits 31:24 of BCRCSEED are {0x0+v}) (v=224..233); 234=hEA (Bits 31:24 of BCRCSEED are 0xEA); 235=hEB (Bits 31:24 of BCRCSEED are 0xEB); 236=hEC (Bits 31:24 of BCRCSEED are 0xEC); 237=hED (Bits 31:24 of BCRCSEED are 0xED); 238=hEE (Bits 31:24 of BCRCSEED are 0xEE); 239=hEF (Bits 31:24 of BCRCSEED are 0xEF); {v}=hF{v-240} (Bits 31:24 of BCRCSEED are {0x0+v}) (v=240..249); 250=hFA (Bits 31:24 of BCRCSEED are 0xFA); 251=hFB (Bits 31:24 of BCRCSEED are 0xFB); 252=hFC (Bits 31:24 of BCRCSEED are 0xFC); 253=hFD (Bits 31:24 of BCRCSEED are 0xFD); 254=hFE (Bits 31:24 of BCRCSEED are 0xFE); 255=hFF (Bits 31:24 of BCRCSEED are 0xFF)
0x300010 CONFIG17 reset 0xFF — Boot Sector Seed for CRC on boot bits 23-16
  [7:0] BCRCSEEDU
    {v}=h{v:02} (Bits 23:16 of BCRCSEED are {0x0+v}) (v=0..9); 10=h0A (Bits 23:16 of BCRCSEED are 0x0A); 11=h0B (Bits 23:16 of BCRCSEED are 0x0B); 12=h0C (Bits 23:16 of BCRCSEED are 0x0C); 13=h0D (Bits 23:16 of BCRCSEED are 0x0D); 14=h0E (Bits 23:16 of BCRCSEED are 0x0E); 15=h0F (Bits 23:16 of BCRCSEED are 0x0F); {v}=h{v-6} (Bits 23:16 of BCRCSEED are {0x0+v}) (v=16..25); 26=h1A (Bits 23:16 of BCRCSEED are 0x1A); 27=h1B (Bits 23:16 of BCRCSEED are 0x1B); 28=h1C (Bits 23:16 of BCRCSEED are 0x1C); 29=h1D (Bits 23:16 of BCRCSEED are 0x1D); 30=h1E (Bits 23:16 of BCRCSEED are 0x1E); 31=h1F (Bits 23:16 of BCRCSEED are 0x1F); {v}=h{v-12} (Bits 23:16 of BCRCSEED are {0x0+v}) (v=32..41); 42=h2A (Bits 23:16 of BCRCSEED are 0x2A); 43=h2B (Bits 23:16 of BCRCSEED are 0x2B); 44=h2C (Bits 23:16 of BCRCSEED are 0x2C); 45=h2D (Bits 23:16 of BCRCSEED are 0x2D); 46=h2E (Bits 23:16 of BCRCSEED are 0x2E); 47=h2F (Bits 23:16 of BCRCSEED are 0x2F); {v}=h{v-18} (Bits 23:16 of BCRCSEED are {0x0+v}) (v=48..57); 58=h3A (Bits 23:16 of BCRCSEED are 0x3A); 59=h3B (Bits 23:16 of BCRCSEED are 0x3B); 60=h3C (Bits 23:16 of BCRCSEED are 0x3C); 61=h3D (Bits 23:16 of BCRCSEED are 0x3D); 62=h3E (Bits 23:16 of BCRCSEED are 0x3E); 63=h3F (Bits 23:16 of BCRCSEED are 0x3F); {v}=h{v-24} (Bits 23:16 of BCRCSEED are {0x0+v}) (v=64..73); 74=h4A (Bits 23:16 of BCRCSEED are 0x4A); 75=h4B (Bits 23:16 of BCRCSEED are 0x4B); 76=h4C (Bits 23:16 of BCRCSEED are 0x4C); 77=h4D (Bits 23:16 of BCRCSEED are 0x4D); 78=h4E (Bits 23:16 of BCRCSEED are 0x4E); 79=h4F (Bits 23:16 of BCRCSEED are 0x4F); {v}=h{v-30} (Bits 23:16 of BCRCSEED are {0x0+v}) (v=80..89); 90=h5A (Bits 23:16 of BCRCSEED are 0x5A); 91=h5B (Bits 23:16 of BCRCSEED are 0x5B); 92=h5C (Bits 23:16 of BCRCSEED are 0x5C); 93=h5D (Bits 23:16 of BCRCSEED are 0x5D); 94=h5E (Bits 23:16 of BCRCSEED are 0x5E); 95=h5F (Bits 23:16 of BCRCSEED are 0x5F); {v}=h{v-36} (Bits 23:16 of BCRCSEED are {0x0+v}) (v=96..105); 106=h6A (Bits 23:16 of BCRCSEED are 0x6A); 107=h6B (Bits 23:16 of BCRCSEED are 0x6B); 108=h6C (Bits 23:16 of BCRCSEED are 0x6C); 109=h6D (Bits 23:16 of BCRCSEED are 0x6D); 110=h6E (Bits 23:16 of BCRCSEED are 0x6E); 111=h6F (Bits 23:16 of BCRCSEED are 0x6F); {v}=h{v-42} (Bits 23:16 of BCRCSEED are {0x0+v}) (v=112..121); 122=h7A (Bits 23:16 of BCRCSEED are 0x7A); 123=h7B (Bits 23:16 of BCRCSEED are 0x7B); 124=h7C (Bits 23:16 of BCRCSEED are 0x7C); 125=h7D (Bits 23:16 of BCRCSEED are 0x7D); 126=h7E (Bits 23:16 of BCRCSEED are 0x7E); 127=h7F (Bits 23:16 of BCRCSEED are 0x7F); {v}=h{v-48} (Bits 23:16 of BCRCSEED are {0x0+v}) (v=128..137); 138=h8A (Bits 23:16 of BCRCSEED are 0x8A); 139=h8B (Bits 23:16 of BCRCSEED are 0x8B); 140=h8C (Bits 23:16 of BCRCSEED are 0x8C); 141=h8D (Bits 23:16 of BCRCSEED are 0x8D); 142=h8E (Bits 23:16 of BCRCSEED are 0x8E); 143=h8F (Bits 23:16 of BCRCSEED are 0x8F); {v}=h{v-54} (Bits 23:16 of BCRCSEED are {0x0+v}) (v=144..153); 154=h9A (Bits 23:16 of BCRCSEED are 0x9A); 155=h9B (Bits 23:16 of BCRCSEED are 0x9B); 156=h9C (Bits 23:16 of BCRCSEED are 0x9C); 157=h9D (Bits 23:16 of BCRCSEED are 0x9D); 158=h9E (Bits 23:16 of BCRCSEED are 0x9E); 159=h9F (Bits 23:16 of BCRCSEED are 0x9F); {v}=hA{v-160} (Bits 23:16 of BCRCSEED are {0x0+v}) (v=160..169); 170=hAA (Bits 23:16 of BCRCSEED are 0xAA); 171=hAB (Bits 23:16 of BCRCSEED are 0xAB); 172=hAC (Bits 23:16 of BCRCSEED are 0xAC); 173=hAD (Bits 23:16 of BCRCSEED are 0xAD); 174=hAE (Bits 23:16 of BCRCSEED are 0xAE); 175=hAF (Bits 23:16 of BCRCSEED are 0xAF); {v}=hB{v-176} (Bits 23:16 of BCRCSEED are {0x0+v}) (v=176..185); 186=hBA (Bits 23:16 of BCRCSEED are 0xBA); 187=hBB (Bits 23:16 of BCRCSEED are 0xBB); 188=hBC (Bits 23:16 of BCRCSEED are 0xBC); 189=hBD (Bits 23:16 of BCRCSEED are 0xBD); 190=hBE (Bits 23:16 of BCRCSEED are 0xBE); 191=hBF (Bits 23:16 of BCRCSEED are 0xBF); {v}=hC{v-192} (Bits 23:16 of BCRCSEED are {0x0+v}) (v=192..201); 202=hCA (Bits 23:16 of BCRCSEED are 0xCA); 203=hCB (Bits 23:16 of BCRCSEED are 0xCB); 204=hCC (Bits 23:16 of BCRCSEED are 0xCC); 205=hCD (Bits 23:16 of BCRCSEED are 0xCD); 206=hCE (Bits 23:16 of BCRCSEED are 0xCE); 207=hCF (Bits 23:16 of BCRCSEED are 0xCF); {v}=hD{v-208} (Bits 23:16 of BCRCSEED are {0x0+v}) (v=208..217); 218=hDA (Bits 23:16 of BCRCSEED are 0xDA); 219=hDB (Bits 23:16 of BCRCSEED are 0xDB); 220=hDC (Bits 23:16 of BCRCSEED are 0xDC); 221=hDD (Bits 23:16 of BCRCSEED are 0xDD); 222=hDE (Bits 23:16 of BCRCSEED are 0xDE); 223=hDF (Bits 23:16 of BCRCSEED are 0xDF); {v}=hE{v-224} (Bits 23:16 of BCRCSEED are {0x0+v}) (v=224..233); 234=hEA (Bits 23:16 of BCRCSEED are 0xEA); 235=hEB (Bits 23:16 of BCRCSEED are 0xEB); 236=hEC (Bits 23:16 of BCRCSEED are 0xEC); 237=hED (Bits 23:16 of BCRCSEED are 0xED); 238=hEE (Bits 23:16 of BCRCSEED are 0xEE); 239=hEF (Bits 23:16 of BCRCSEED are 0xEF); {v}=hF{v-240} (Bits 23:16 of BCRCSEED are {0x0+v}) (v=240..249); 250=hFA (Bits 23:16 of BCRCSEED are 0xFA); 251=hFB (Bits 23:16 of BCRCSEED are 0xFB); 252=hFC (Bits 23:16 of BCRCSEED are 0xFC); 253=hFD (Bits 23:16 of BCRCSEED are 0xFD); 254=hFE (Bits 23:16 of BCRCSEED are 0xFE); 255=hFF (Bits 23:16 of BCRCSEED are 0xFF)
0x300011 CONFIG18 reset 0xFF — Boot Sector Seed for CRC on boot bits 15-8
  [7:0] BCRCSEEDH
    {v}=h{v:02} (Bits 15:8 of BCRCSEED are {0x0+v}) (v=0..9); 10=h0A (Bits 15:8 of BCRCSEED are 0x0A); 11=h0B (Bits 15:8 of BCRCSEED are 0x0B); 12=h0C (Bits 15:8 of BCRCSEED are 0x0C); 13=h0D (Bits 15:8 of BCRCSEED are 0x0D); 14=h0E (Bits 15:8 of BCRCSEED are 0x0E); 15=h0F (Bits 15:8 of BCRCSEED are 0x0F); {v}=h{v-6} (Bits 15:8 of BCRCSEED are {0x0+v}) (v=16..25); 26=h1A (Bits 15:8 of BCRCSEED are 0x1A); 27=h1B (Bits 15:8 of BCRCSEED are 0x1B); 28=h1C (Bits 15:8 of BCRCSEED are 0x1C); 29=h1D (Bits 15:8 of BCRCSEED are 0x1D); 30=h1E (Bits 15:8 of BCRCSEED are 0x1E); 31=h1F (Bits 15:8 of BCRCSEED are 0x1F); {v}=h{v-12} (Bits 15:8 of BCRCSEED are {0x0+v}) (v=32..41); 42=h2A (Bits 15:8 of BCRCSEED are 0x2A); 43=h2B (Bits 15:8 of BCRCSEED are 0x2B); 44=h2C (Bits 15:8 of BCRCSEED are 0x2C); 45=h2D (Bits 15:8 of BCRCSEED are 0x2D); 46=h2E (Bits 15:8 of BCRCSEED are 0x2E); 47=h2F (Bits 15:8 of BCRCSEED are 0x2F); {v}=h{v-18} (Bits 15:8 of BCRCSEED are {0x0+v}) (v=48..57); 58=h3A (Bits 15:8 of BCRCSEED are 0x3A); 59=h3B (Bits 15:8 of BCRCSEED are 0x3B); 60=h3C (Bits 15:8 of BCRCSEED are 0x3C); 61=h3D (Bits 15:8 of BCRCSEED are 0x3D); 62=h3E (Bits 15:8 of BCRCSEED are 0x3E); 63=h3F (Bits 15:8 of BCRCSEED are 0x3F); {v}=h{v-24} (Bits 15:8 of BCRCSEED are {0x0+v}) (v=64..73); 74=h4A (Bits 15:8 of BCRCSEED are 0x4A); 75=h4B (Bits 15:8 of BCRCSEED are 0x4B); 76=h4C (Bits 15:8 of BCRCSEED are 0x4C); 77=h4D (Bits 15:8 of BCRCSEED are 0x4D); 78=h4E (Bits 15:8 of BCRCSEED are 0x4E); 79=h4F (Bits 15:8 of BCRCSEED are 0x4F); {v}=h{v-30} (Bits 15:8 of BCRCSEED are {0x0+v}) (v=80..89); 90=h5A (Bits 15:8 of BCRCSEED are 0x5A); 91=h5B (Bits 15:8 of BCRCSEED are 0x5B); 92=h5C (Bits 15:8 of BCRCSEED are 0x5C); 93=h5D (Bits 15:8 of BCRCSEED are 0x5D); 94=h5E (Bits 15:8 of BCRCSEED are 0x5E); 95=h5F (Bits 15:8 of BCRCSEED are 0x5F); {v}=h{v-36} (Bits 15:8 of BCRCSEED are {0x0+v}) (v=96..105); 106=h6A (Bits 15:8 of BCRCSEED are 0x6A); 107=h6B (Bits 15:8 of BCRCSEED are 0x6B); 108=h6C (Bits 15:8 of BCRCSEED are 0x6C); 109=h6D (Bits 15:8 of BCRCSEED are 0x6D); 110=h6E (Bits 15:8 of BCRCSEED are 0x6E); 111=h6F (Bits 15:8 of BCRCSEED are 0x6F); {v}=h{v-42} (Bits 15:8 of BCRCSEED are {0x0+v}) (v=112..121); 122=h7A (Bits 15:8 of BCRCSEED are 0x7A); 123=h7B (Bits 15:8 of BCRCSEED are 0x7B); 124=h7C (Bits 15:8 of BCRCSEED are 0x7C); 125=h7D (Bits 15:8 of BCRCSEED are 0x7D); 126=h7E (Bits 15:8 of BCRCSEED are 0x7E); 127=h7F (Bits 15:8 of BCRCSEED are 0x7F); {v}=h{v-48} (Bits 15:8 of BCRCSEED are {0x0+v}) (v=128..137); 138=h8A (Bits 15:8 of BCRCSEED are 0x8A); 139=h8B (Bits 15:8 of BCRCSEED are 0x8B); 140=h8C (Bits 15:8 of BCRCSEED are 0x8C); 141=h8D (Bits 15:8 of BCRCSEED are 0x8D); 142=h8E (Bits 15:8 of BCRCSEED are 0x8E); 143=h8F (Bits 15:8 of BCRCSEED are 0x8F); {v}=h{v-54} (Bits 15:8 of BCRCSEED are {0x0+v}) (v=144..153); 154=h9A (Bits 15:8 of BCRCSEED are 0x9A); 155=h9B (Bits 15:8 of BCRCSEED are 0x9B); 156=h9C (Bits 15:8 of BCRCSEED are 0x9C); 157=h9D (Bits 15:8 of BCRCSEED are 0x9D); 158=h9E (Bits 15:8 of BCRCSEED are 0x9E); 159=h9F (Bits 15:8 of BCRCSEED are 0x9F); {v}=hA{v-160} (Bits 15:8 of BCRCSEED are {0x0+v}) (v=160..169); 170=hAA (Bits 15:8 of BCRCSEED are 0xAA); 171=hAB (Bits 15:8 of BCRCSEED are 0xAB); 172=hAC (Bits 15:8 of BCRCSEED are 0xAC); 173=hAD (Bits 15:8 of BCRCSEED are 0xAD); 174=hAE (Bits 15:8 of BCRCSEED are 0xAE); 175=hAF (Bits 15:8 of BCRCSEED are 0xAF); {v}=hB{v-176} (Bits 15:8 of BCRCSEED are {0x0+v}) (v=176..185); 186=hBA (Bits 15:8 of BCRCSEED are 0xBA); 187=hBB (Bits 15:8 of BCRCSEED are 0xBB); 188=hBC (Bits 15:8 of BCRCSEED are 0xBC); 189=hBD (Bits 15:8 of BCRCSEED are 0xBD); 190=hBE (Bits 15:8 of BCRCSEED are 0xBE); 191=hBF (Bits 15:8 of BCRCSEED are 0xBF); {v}=hC{v-192} (Bits 15:8 of BCRCSEED are {0x0+v}) (v=192..201); 202=hCA (Bits 15:8 of BCRCSEED are 0xCA); 203=hCB (Bits 15:8 of BCRCSEED are 0xCB); 204=hCC (Bits 15:8 of BCRCSEED are 0xCC); 205=hCD (Bits 15:8 of BCRCSEED are 0xCD); 206=hCE (Bits 15:8 of BCRCSEED are 0xCE); 207=hCF (Bits 15:8 of BCRCSEED are 0xCF); {v}=hD{v-208} (Bits 15:8 of BCRCSEED are {0x0+v}) (v=208..217); 218=hDA (Bits 15:8 of BCRCSEED are 0xDA); 219=hDB (Bits 15:8 of BCRCSEED are 0xDB); 220=hDC (Bits 15:8 of BCRCSEED are 0xDC); 221=hDD (Bits 15:8 of BCRCSEED are 0xDD); 222=hDE (Bits 15:8 of BCRCSEED are 0xDE); 223=hDF (Bits 15:8 of BCRCSEED are 0xDF); {v}=hE{v-224} (Bits 15:8 of BCRCSEED are {0x0+v}) (v=224..233); 234=hEA (Bits 15:8 of BCRCSEED are 0xEA); 235=hEB (Bits 15:8 of BCRCSEED are 0xEB); 236=hEC (Bits 15:8 of BCRCSEED are 0xEC); 237=hED (Bits 15:8 of BCRCSEED are 0xED); 238=hEE (Bits 15:8 of BCRCSEED are 0xEE); 239=hEF (Bits 15:8 of BCRCSEED are 0xEF); {v}=hF{v-240} (Bits 15:8 of BCRCSEED are {0x0+v}) (v=240..249); 250=hFA (Bits 15:8 of BCRCSEED are 0xFA); 251=hFB (Bits 15:8 of BCRCSEED are 0xFB); 252=hFC (Bits 15:8 of BCRCSEED are 0xFC); 253=hFD (Bits 15:8 of BCRCSEED are 0xFD); 254=hFE (Bits 15:8 of BCRCSEED are 0xFE); 255=hFF (Bits 15:8 of BCRCSEED are 0xFF)
